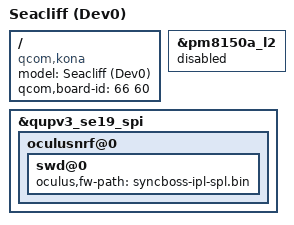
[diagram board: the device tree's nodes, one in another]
/dts-v1/;
/plugin/;

#include "seacliff-p0.dtsi"

/ {
	model = "Seacliff (Dev0)";
	compatible = "qcom,kona";
	qcom,board-id = <66 60>;
};

&pm8150a_l2 {
	status = "disabled";
};

&qupv3_se19_spi {
	oculusnrf@0 {
		swd@0 {
			oculus,fw-path = "syncboss-ipl-spl.bin";
		};
	};
};
